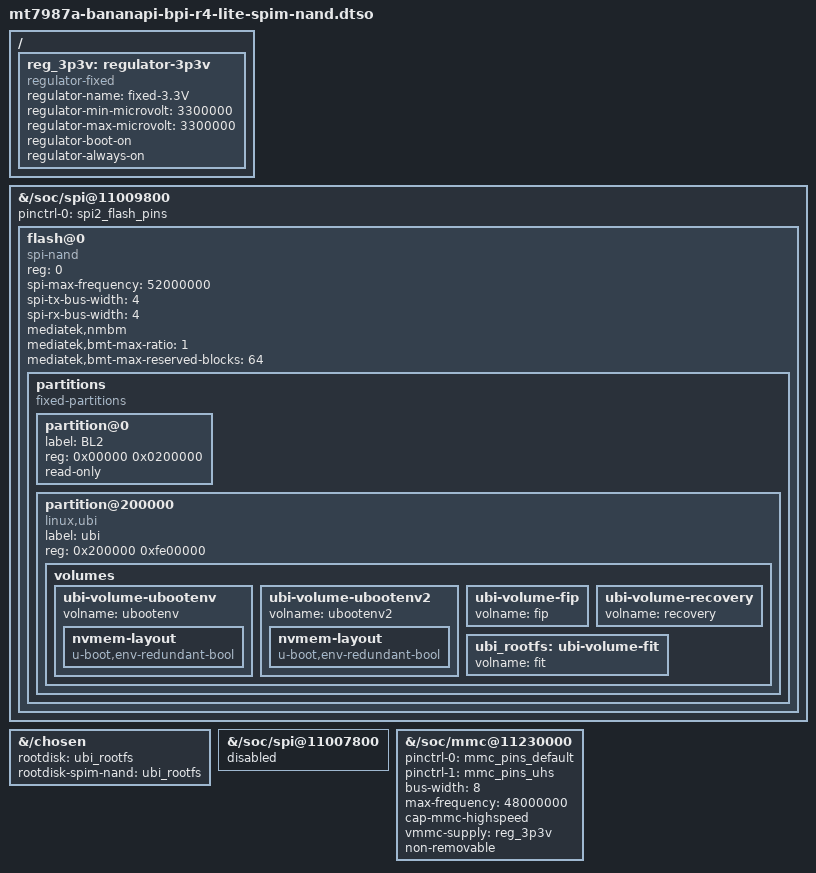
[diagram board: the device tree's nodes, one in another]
// SPDX-License-Identifier: (GPL-2.0 OR MIT)

/dts-v1/;
/plugin/;

/ {
	fragment@0 {
		target-path = "/soc/spi@11009800";
		__overlay__ {
			pinctrl-names = "default";
			pinctrl-0 = <&spi2_flash_pins>;
			status = "okay";

			flash@0 {
				compatible = "spi-nand";
				reg = <0>;
				spi-max-frequency = <52000000>;
				spi-tx-bus-width = <4>;
				spi-rx-bus-width = <4>;
				mediatek,nmbm;
				mediatek,bmt-max-ratio = <1>;
				mediatek,bmt-max-reserved-blocks = <64>;

				partitions {
					compatible = "fixed-partitions";
					#address-cells = <1>;
					#size-cells = <1>;

					partition@0 {
						label = "BL2";
						reg = <0x00000 0x0200000>;
						read-only;
					};

					partition@200000 {
						label = "ubi";
						reg = <0x200000 0xfe00000>;
						compatible = "linux,ubi";

						volumes {
							ubi-volume-ubootenv {
								volname = "ubootenv";
								nvmem-layout {
									compatible = "u-boot,env-redundant-bool";
									};
							};

							ubi-volume-ubootenv2 {
								volname = "ubootenv2";
								nvmem-layout {
									compatible = "u-boot,env-redundant-bool";
								};
							};

							ubi-volume-fip {
								volname = "fip";
							};

							ubi-volume-recovery {
								volname = "recovery";
							};

							ubi_rootfs: ubi-volume-fit {
								volname = "fit";
							};
						};
					};
				};
			};
		};
	};

	fragment@1 {
		target-path = "/chosen";
		__overlay__ {
			rootdisk = <&ubi_rootfs>;
			rootdisk-spim-nand = <&ubi_rootfs>;
		};
	};

        fragment@2 {
                target-path = "/";
                __overlay__ {
                        reg_3p3v: regulator-3p3v {
                                compatible = "regulator-fixed";
                                regulator-name = "fixed-3.3V";
                                regulator-min-microvolt = <3300000>;
                                regulator-max-microvolt = <3300000>;
                                regulator-boot-on;
                                regulator-always-on;
                        };  
                };  
        };

        fragment@3 {
                target-path = "/soc/spi@11007800";
                __overlay__ {
                        status = "disabled";
                };  
        };

        fragment@4 {
                target-path = "/soc/mmc@11230000";
                __overlay__ {
                        pinctrl-names = "default", "state_uhs";
                        pinctrl-0 = <&mmc_pins_default>;
                        pinctrl-1 = <&mmc_pins_uhs>;
                        bus-width = <8>;
                        max-frequency = <48000000>;
                        cap-mmc-highspeed;
                        vmmc-supply = <&reg_3p3v>;
                        non-removable;
                        status = "okay"; 
                        #address-cells = <1>;
                        #size-cells = <0>;
		};
	};
};
